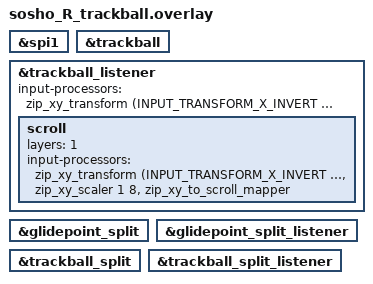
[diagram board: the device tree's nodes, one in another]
#include "sosho_R.dtsi"

&spi1 { status = "okay"; };
&trackball { status = "okay"; };
&trackball_listener {
	status = "okay";
	input-processors = <&zip_xy_transform (INPUT_TRANSFORM_X_INVERT | INPUT_TRANSFORM_Y_INVERT)>;

	scroll {
		layers = <1>;
		input-processors = <
			&zip_xy_transform (INPUT_TRANSFORM_X_INVERT | INPUT_TRANSFORM_Y_INVERT)
			&zip_xy_scaler 1 8
			&zip_xy_to_scroll_mapper
		>;
	};
};

&glidepoint_split { status = "okay"; };
&glidepoint_split_listener {
    status = "okay";
/* input-processors = <&zip_xy_scaler 2 1>; */
};

&trackball_split { status = "okay"; };
&trackball_split_listener { status = "okay"; };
